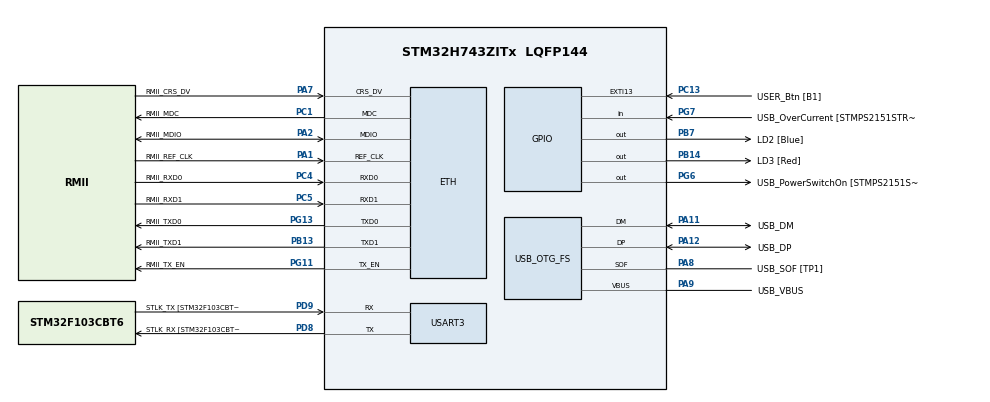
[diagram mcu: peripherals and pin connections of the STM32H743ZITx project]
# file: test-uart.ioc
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Mcu.Family=STM32H7
NVIC.USART3_IRQn=true\:0\:0\:false\:false\:true\:true\:true
RCC.CortexFreq_Value=120000000
PG6.Signal=GPIO_Output
PH0-OSC_IN\ (PH0).Signal=RCC_OSC_IN
PB14.GPIO_Label=LD3 [Red]
PC15-OSC32_OUT\ (OSC32_OUT).Mode=LSE-External-Oscillator
PG6.GPIO_Label=USB_PowerSwitchOn [STMPS2151STR_EN]
RCC.SYSCLKSourceVirtual=RCC_SYSCLKSOURCE_PLLCLK
RCC.PLLFRACN=0
CRC.InputDataFormat=CRC_INPUTDATA_FORMAT_BYTES
PA11.Mode=Device_Only
PC5.Mode=RMII
PC13.GPIO_Label=USER_Btn [B1]
PB13.GPIO_Label=RMII_TXD1
PB13.Signal=ETH_TXD1
PG13.Signal=ETH_TXD0
PD9.Mode=Asynchronous
PG11.Signal=ETH_TX_EN
RCC.SYSCLKSource=RCC_SYSCLKSOURCE_PLLCLK
ProjectManager.StackSize=0x400
USART3.VirtualMode-Asynchronous=VM_ASYNC
PA12.Signal=USB_OTG_FS_DP
RCC.HCLKFreq_Value=120000000
RCC.APB2TimFreq_Value=216000000
PD8.Signal=USART3_TX
RCC.AHBFreq_Value=216000000
RCC.HSE_VALUE=8000000
RCC.DIVM1=1
RCC.PLLMUL=RCC_PLL_MUL9
PC4.GPIO_Label=RMII_RXD0
PA10.GPIO_Label=USB_ID
PB7.Signal=GPIO_Output
PA8.Signal=USB_OTG_FS_SOF
PG13.Mode=RMII
RCC.APB3Freq_Value=120000000
PB7.GPIO_Label=LD2 [Blue]
Mcu.Package=LQFP144
PA2.GPIO_Label=RMII_MDIO
PA10.Signal=USB_OTG_FS_ID
USB_OTG_FS.VirtualMode=Device_Only
PC14-OSC32_IN\ (OSC32_IN).Mode=LSE-External-Oscillator
RCC.APB2CLKDivider=RCC_HCLK_DIV2
RCC.APB4Freq_Value=120000000
RCC.APB1TimFreq_Value=108000000
PG11.GPIO_Label=RMII_TX_EN
PC5.Signal=ETH_RXD1
PB13.Mode=RMII
PH0-OSC_IN\ (PH0).Mode=HSE-External-Clock-Source
PC4.Mode=RMII
RCC.DIVQ1=4
PA7.Mode=RMII
PG7.Signal=GPIO_Input
PD9.GPIO_Label=STLK_TX [STM32F103CBT6_PA2]
PC13.Signal=GPXTI13
PA9.GPIO_Label=USB_VBUS
PC4.Signal=ETH_RXD0
PA11.GPIO_Label=USB_DM
RCC.D2PPRE1=RCC_APB1_DIV2
PD9.Signal=USART3_RX
RCC.APB1CLKDivider=RCC_HCLK_DIV4
PG13.GPIO_Label=RMII_TXD0
CRC.GeneratingPolynomial=X4+X3+X2+X0
PA12.GPIO_Label=USB_DP
RCC.PWR_Regulator_Voltage_Scale=PWR_REGULATOR_VOLTAGE_SCALE1
PH1-OSC_OUT\ (PH1).Signal=RCC_OSC_OUT
PD8.GPIO_Label=STLK_RX [STM32F103CBT6_PA3]
CRC.DefaultPolynomialUse=DEFAULT_POLYNOMIAL_DISABLE
PA9.Mode=Activate_VBUS
PA8.GPIO_Label=USB_SOF [TP1]
ProjectManager.TargetToolchain=STM32CubeIDE
PC15-OSC32_OUT\ (OSC32_OUT).Signal=RCC_OSC32_OUT
PA9.Signal=USB_OTG_FS_VBUS
RCC.DIVN1=30
RCC.USBFreq_Value=60000000
PD8.Mode=Asynchronous
PA1.Signal=ETH_REF_CLK
PB14.Signal=GPIO_Output
board=NUCLEO-H743ZI
RCC.VCOOutputFreq_Value=432000000
RCC.APB2Freq_Value=120000000
PA1.Mode=RMII
RCC.PRESCALERUSB=RCC_USBCLKSOURCE_PLL_DIV1_5
PG7.GPIO_Label=USB_OverCurrent [STMPS2151STR_FAULT]
RCC.ADCFreq_Value=16125000
PA1.GPIO_Label=RMII_REF_CLK
PC1.GPIO_Label=RMII_MDC
CRC.InitValue=0xC4
Mcu.Name=STM32H743ZITx
PA2.Signal=ETH_MDIO
RCC.48MHZClocksFreq_Value=24000000
RCC.SYSCLKFreq_VALUE=120000000
ETH.MediaInterface=HAL_ETH_RMII_MODE
PA7.GPIO_Label=RMII_CRS_DV
PA12.Mode=Device_Only
PC5.GPIO_Label=RMII_RXD1
PC14-OSC32_IN\ (OSC32_IN).Signal=RCC_OSC32_IN
CRC.DefaultInitValueUse=DEFAULT_INIT_VALUE_DISABLE
PG11.Mode=RMII
PA11.Signal=USB_OTG_FS_DM
ProjectManager.HeapSize=0x200
RCC.HSI_VALUE=64000000
RCC.PLLQ=9
NVIC.PriorityGroup=NVIC_PRIORITYGROUP_4
PH0-OSC_IN\ (PH0).GPIO_Label=MCO
RCC.PLLM=25
RCC.PLLN=432
PA2.Mode=RMII
PA8.Mode=Activate_SOF_FS
RCC.APB1Freq_Value=60000000
VP_CRC_VS_CRC.Mode=CRC_Activate
PC1.Signal=ETH_MDC
PC1.Mode=RMII
CRC.CRCLength=CRC_POLYLENGTH_8B
PA7.Signal=ETH_CRS_DV

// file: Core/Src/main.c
/* USER CODE BEGIN Header */
/**
  ******************************************************************************
  * @file           : main.c
  * @brief          : Main program body
  ******************************************************************************
  * @attention
  *
  * <h2><center>&copy; Copyright (c) 2022 STMicroelectronics.
  * All rights reserved.</center></h2>
  *
  * This software component is licensed by ST under BSD 3-Clause license,
  * the "License"; You may not use this file except in compliance with the
  * License. You may obtain a copy of the License at:
  *                        opensource.org/licenses/BSD-3-Clause
  *
  ******************************************************************************
  */
/* USER CODE END Header */
#include "main.h"
#include "crc.h"
#include "eth.h"
#include "usart.h"
#include "usb_otg.h"
#include "gpio.h"

/* USER CODE BEGIN Includes */
#include "ARMsProtocol.h"
/* USER CODE END Includes */

/* USER CODE BEGIN PV */
uint32_t timestamp;
/* USER CODE END PV */

void SystemClock_Config(void);

int main(void)
{

  /* MCU Configuration--------------------------------------------------------*/

  /* Reset of all peripherals, Initializes the Flash interface and the Systick. */
  HAL_Init();

  /* Configure the system clock */
  SystemClock_Config();

  /* Initialize all configured peripherals */
  MX_GPIO_Init();
  MX_ETH_Init();
  MX_USART3_UART_Init();
  MX_USB_OTG_FS_PCD_Init();
  MX_CRC_Init();
  /* USER CODE BEGIN 2 */
  ARMsProtocol_FUNC_Init();
  /* USER CODE END 2 */

  /* Infinite loop */
  while (1)
  {

    /* USER CODE BEGIN 3 */
	  if(HAL_GetTick() - timestamp >= 200){
		  timestamp = HAL_GetTick();
		  ARMsProtocol_FUNC_Interface();
	  }
  }
  /* USER CODE END 3 */
}

void SystemClock_Config(void)
{
  RCC_OscInitTypeDef RCC_OscInitStruct = {0};
  RCC_ClkInitTypeDef RCC_ClkInitStruct = {0};

  /** Supply configuration update enable
  */
  HAL_PWREx_ConfigSupply(PWR_LDO_SUPPLY);
  /** Configure the main internal regulator output voltage
  */
  __HAL_PWR_VOLTAGESCALING_CONFIG(PWR_REGULATOR_VOLTAGE_SCALE1);

  while(!__HAL_PWR_GET_FLAG(PWR_FLAG_VOSRDY)) {}
  /** Initializes the RCC Oscillators according to the specified parameters
  * in the RCC_OscInitTypeDef structure.
  */
  RCC_OscInitStruct.OscillatorType = RCC_OSCILLATORTYPE_HSE;
  RCC_OscInitStruct.HSEState = RCC_HSE_BYPASS;
  RCC_OscInitStruct.PLL.PLLState = RCC_PLL_ON;
  RCC_OscInitStruct.PLL.PLLSource = RCC_PLLSOURCE_HSE;
  RCC_OscInitStruct.PLL.PLLM = 1;
  RCC_OscInitStruct.PLL.PLLN = 30;
  RCC_OscInitStruct.PLL.PLLP = 2;
  RCC_OscInitStruct.PLL.PLLQ = 4;
  RCC_OscInitStruct.PLL.PLLR = 2;
  RCC_OscInitStruct.PLL.PLLRGE = RCC_PLL1VCIRANGE_3;
  RCC_OscInitStruct.PLL.PLLVCOSEL = RCC_PLL1VCOWIDE;
  RCC_OscInitStruct.PLL.PLLFRACN = 0;
  if (HAL_RCC_OscConfig(&RCC_OscInitStruct) != HAL_OK)
  {
    Error_Handler();
  }
  /** Initializes the CPU, AHB and APB buses clocks
  */
  RCC_ClkInitStruct.ClockType = RCC_CLOCKTYPE_HCLK|RCC_CLOCKTYPE_SYSCLK
                              |RCC_CLOCKTYPE_PCLK1|RCC_CLOCKTYPE_PCLK2
                              |RCC_CLOCKTYPE_D3PCLK1|RCC_CLOCKTYPE_D1PCLK1;
  RCC_ClkInitStruct.SYSCLKSource = RCC_SYSCLKSOURCE_PLLCLK;
  RCC_ClkInitStruct.SYSCLKDivider = RCC_SYSCLK_DIV1;
  RCC_ClkInitStruct.AHBCLKDivider = RCC_HCLK_DIV1;
  RCC_ClkInitStruct.APB3CLKDivider = RCC_APB3_DIV1;
  RCC_ClkInitStruct.APB1CLKDivider = RCC_APB1_DIV2;
  RCC_ClkInitStruct.APB2CLKDivider = RCC_APB2_DIV1;
  RCC_ClkInitStruct.APB4CLKDivider = RCC_APB4_DIV1;

  if (HAL_RCC_ClockConfig(&RCC_ClkInitStruct, FLASH_LATENCY_1) != HAL_OK)
  {
    Error_Handler();
  }
}

void Error_Handler(void)
{
  __disable_irq();
  while (1)
  {
  }
}

/************************ (C) COPYRIGHT STMicroelectronics *****END OF FILE****/
